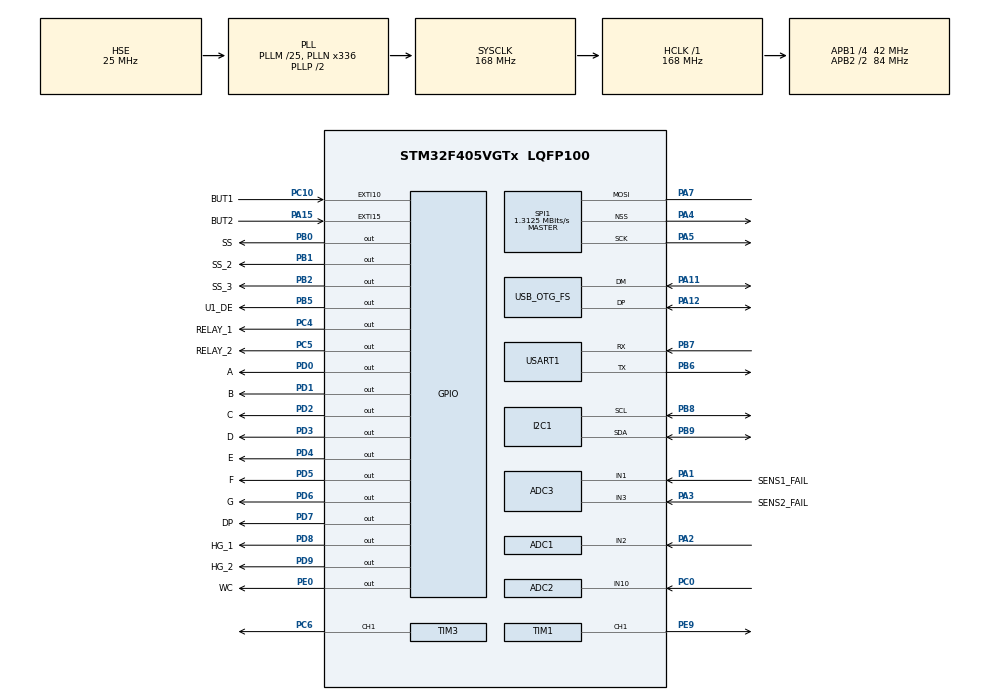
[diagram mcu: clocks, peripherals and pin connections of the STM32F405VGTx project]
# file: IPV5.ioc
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ADC1.Channel-4\#ChannelRegularConversion=ADC_CHANNEL_2
ADC1.ClockPrescaler=ADC_CLOCK_SYNC_PCLK_DIV8
ADC1.ContinuousConvMode=DISABLE
ADC1.DMAContinuousRequests=ENABLE
ADC1.DataAlign=ADC_DATAALIGN_RIGHT
ADC1.DiscontinuousConvMode=DISABLE
ADC1.EOCSelection=ADC_EOC_SINGLE_CONV
ADC1.EnableAnalogWatchDog=false
ADC1.ExternalTrigConv=ADC_EXTERNALTRIGCONV_T2_TRGO
ADC1.ExternalTrigConvEdge=ADC_EXTERNALTRIGCONVEDGE_RISING
ADC1.InjNumberOfConversion=0
ADC1.NbrOfConversion=1
ADC1.NbrOfConversionFlag=1
ADC1.Rank-4\#ChannelRegularConversion=1
ADC1.Resolution=ADC_RESOLUTION_12B
ADC1.SamplingTime-4\#ChannelRegularConversion=ADC_SAMPLETIME_15CYCLES
ADC1.ScanConvMode=DISABLE
ADC1.master=1
ADC2.Channel-0\#ChannelRegularConversion=ADC_CHANNEL_10
ADC2.ClockPrescaler=ADC_CLOCK_SYNC_PCLK_DIV8
ADC2.ExternalTrigConv=ADC_EXTERNALTRIGCONV_T2_TRGO
ADC2.ExternalTrigConvEdge=ADC_EXTERNALTRIGCONVEDGE_FALLING
ADC2.NbrOfConversionFlag=1
ADC2.Rank-0\#ChannelRegularConversion=1
ADC2.SamplingTime-0\#ChannelRegularConversion=ADC_SAMPLETIME_3CYCLES
ADC3.Channel-0\#ChannelRegularConversion=ADC_CHANNEL_1
ADC3.Channel-1\#ChannelInjectedConversion=ADC_CHANNEL_1
ADC3.Channel-2\#ChannelInjectedConversion=ADC_CHANNEL_3
ADC3.ClockPrescaler=ADC_CLOCK_SYNC_PCLK_DIV8
ADC3.ContinuousConvMode=DISABLE
ADC3.DiscontinuousConvMode=DISABLE
ADC3.ExternalTrigInjecConv=ADC_INJECTED_SOFTWARE_START
ADC3.InjNumberOfConversion=2
ADC3.InjectedConvMode=AutoInjected
ADC3.InjectedOffset-1\#ChannelInjectedConversion=0
ADC3.InjectedOffset-2\#ChannelInjectedConversion=0
ADC3.InjectedRank-1\#ChannelInjectedConversion=1
ADC3.InjectedRank-2\#ChannelInjectedConversion=2
ADC3.NbrOfConversion=1
ADC3.NbrOfConversionFlag=1
ADC3.Rank-0\#ChannelRegularConversion=1
ADC3.SamplingTime-0\#ChannelRegularConversion=ADC_SAMPLETIME_480CYCLES
ADC3.SamplingTime-1\#ChannelInjectedConversion=ADC_SAMPLETIME_480CYCLES
ADC3.SamplingTime-2\#ChannelInjectedConversion=ADC_SAMPLETIME_480CYCLES
ADC3.ScanConvMode=ENABLE
Dma.ADC1.6.Direction=DMA_PERIPH_TO_MEMORY
Dma.ADC1.6.FIFOMode=DMA_FIFOMODE_ENABLE
Dma.ADC1.6.FIFOThreshold=DMA_FIFO_THRESHOLD_FULL
Dma.ADC1.6.Instance=DMA2_Stream4
Dma.ADC1.6.MemBurst=DMA_MBURST_INC4
Dma.ADC1.6.MemDataAlignment=DMA_MDATAALIGN_WORD
Dma.ADC1.6.MemInc=DMA_MINC_ENABLE
Dma.ADC1.6.Mode=DMA_NORMAL
Dma.ADC1.6.PeriphBurst=DMA_PBURST_SINGLE
Dma.ADC1.6.PeriphDataAlignment=DMA_PDATAALIGN_WORD
Dma.ADC1.6.PeriphInc=DMA_PINC_DISABLE
Dma.ADC1.6.Priority=DMA_PRIORITY_MEDIUM
Dma.ADC2.7.Direction=DMA_PERIPH_TO_MEMORY
Dma.ADC2.7.FIFOMode=DMA_FIFOMODE_ENABLE
Dma.ADC2.7.FIFOThreshold=DMA_FIFO_THRESHOLD_FULL
Dma.ADC2.7.Instance=DMA2_Stream2
Dma.ADC2.7.MemBurst=DMA_MBURST_INC4
Dma.ADC2.7.MemDataAlignment=DMA_MDATAALIGN_WORD
Dma.ADC2.7.MemInc=DMA_MINC_ENABLE
Dma.ADC2.7.Mode=DMA_NORMAL
Dma.ADC2.7.PeriphBurst=DMA_PBURST_SINGLE
Dma.ADC2.7.PeriphDataAlignment=DMA_PDATAALIGN_WORD
Dma.ADC2.7.PeriphInc=DMA_PINC_DISABLE
Dma.ADC2.7.Priority=DMA_PRIORITY_MEDIUM
Dma.I2C1_RX.1.Direction=DMA_PERIPH_TO_MEMORY
Dma.I2C1_RX.1.FIFOMode=DMA_FIFOMODE_DISABLE
Dma.I2C1_RX.1.Instance=DMA1_Stream0
Dma.I2C1_RX.1.MemDataAlignment=DMA_MDATAALIGN_BYTE
Dma.I2C1_RX.1.MemInc=DMA_MINC_ENABLE
Dma.I2C1_RX.1.Mode=DMA_NORMAL
Dma.I2C1_RX.1.PeriphDataAlignment=DMA_PDATAALIGN_BYTE
Dma.I2C1_RX.1.PeriphInc=DMA_PINC_DISABLE
Dma.I2C1_RX.1.Priority=DMA_PRIORITY_LOW
Dma.I2C1_TX.0.Direction=DMA_MEMORY_TO_PERIPH
Dma.I2C1_TX.0.FIFOMode=DMA_FIFOMODE_DISABLE
Dma.I2C1_TX.0.Instance=DMA1_Stream7
Dma.I2C1_TX.0.MemDataAlignment=DMA_MDATAALIGN_BYTE
Dma.I2C1_TX.0.MemInc=DMA_MINC_ENABLE
Dma.I2C1_TX.0.Mode=DMA_NORMAL
Dma.I2C1_TX.0.PeriphDataAlignment=DMA_PDATAALIGN_BYTE
Dma.I2C1_TX.0.PeriphInc=DMA_PINC_DISABLE
Dma.I2C1_TX.0.Priority=DMA_PRIORITY_LOW
Dma.Request0=I2C1_TX
Dma.Request1=I2C1_RX
Dma.Request2=SPI1_RX
Dma.Request3=SPI1_TX
Dma.Request4=USART1_RX
Dma.Request5=USART1_TX
Dma.Request6=ADC1
Dma.Request7=ADC2
Dma.Request8=TIM8_UP
Dma.SPI1_RX.2.Direction=DMA_PERIPH_TO_MEMORY
Dma.SPI1_RX.2.FIFOMode=DMA_FIFOMODE_ENABLE
Dma.SPI1_RX.2.FIFOThreshold=DMA_FIFO_THRESHOLD_FULL
Dma.SPI1_RX.2.Instance=DMA2_Stream0
Dma.SPI1_RX.2.MemBurst=DMA_MBURST_SINGLE
Dma.SPI1_RX.2.MemDataAlignment=DMA_MDATAALIGN_HALFWORD
Dma.SPI1_RX.2.MemInc=DMA_MINC_ENABLE
Dma.SPI1_RX.2.Mode=DMA_NORMAL
Dma.SPI1_RX.2.PeriphBurst=DMA_PBURST_SINGLE
Dma.SPI1_RX.2.PeriphDataAlignment=DMA_PDATAALIGN_HALFWORD
Dma.SPI1_RX.2.PeriphInc=DMA_PINC_DISABLE
Dma.SPI1_RX.2.Priority=DMA_PRIORITY_MEDIUM
Dma.SPI1_TX.3.Direction=DMA_MEMORY_TO_PERIPH
Dma.SPI1_TX.3.FIFOMode=DMA_FIFOMODE_ENABLE
Dma.SPI1_TX.3.FIFOThreshold=DMA_FIFO_THRESHOLD_FULL
Dma.SPI1_TX.3.Instance=DMA2_Stream3
Dma.SPI1_TX.3.MemBurst=DMA_MBURST_SINGLE
Dma.SPI1_TX.3.MemDataAlignment=DMA_MDATAALIGN_HALFWORD
Dma.SPI1_TX.3.MemInc=DMA_MINC_ENABLE
Dma.SPI1_TX.3.Mode=DMA_NORMAL
Dma.SPI1_TX.3.PeriphBurst=DMA_PBURST_SINGLE
Dma.SPI1_TX.3.PeriphDataAlignment=DMA_PDATAALIGN_HALFWORD
Dma.SPI1_TX.3.PeriphInc=DMA_PINC_DISABLE
Dma.SPI1_TX.3.Priority=DMA_PRIORITY_LOW
Dma.TIM8_UP.8.Direction=DMA_MEMORY_TO_PERIPH
Dma.TIM8_UP.8.FIFOMode=DMA_FIFOMODE_ENABLE
Dma.TIM8_UP.8.FIFOThreshold=DMA_FIFO_THRESHOLD_FULL
Dma.TIM8_UP.8.Instance=DMA2_Stream1
Dma.TIM8_UP.8.MemBurst=DMA_MBURST_INC4
Dma.TIM8_UP.8.MemDataAlignment=DMA_MDATAALIGN_WORD
Dma.TIM8_UP.8.MemInc=DMA_MINC_ENABLE
Dma.TIM8_UP.8.Mode=DMA_CIRCULAR
Dma.TIM8_UP.8.PeriphBurst=DMA_PBURST_SINGLE
Dma.TIM8_UP.8.PeriphDataAlignment=DMA_PDATAALIGN_WORD
Dma.TIM8_UP.8.PeriphInc=DMA_PINC_DISABLE
Dma.TIM8_UP.8.Priority=DMA_PRIORITY_HIGH
Dma.USART1_RX.4.Direction=DMA_PERIPH_TO_MEMORY
Dma.USART1_RX.4.FIFOMode=DMA_FIFOMODE_ENABLE
Dma.USART1_RX.4.FIFOThreshold=DMA_FIFO_THRESHOLD_FULL
Dma.USART1_RX.4.Instance=DMA2_Stream5
Dma.USART1_RX.4.MemBurst=DMA_MBURST_SINGLE
Dma.USART1_RX.4.MemDataAlignment=DMA_MDATAALIGN_BYTE
Dma.USART1_RX.4.MemInc=DMA_MINC_ENABLE
Dma.USART1_RX.4.Mode=DMA_NORMAL
Dma.USART1_RX.4.PeriphBurst=DMA_PBURST_SINGLE
Dma.USART1_RX.4.PeriphDataAlignment=DMA_PDATAALIGN_BYTE
Dma.USART1_RX.4.PeriphInc=DMA_PINC_DISABLE
Dma.USART1_RX.4.Priority=DMA_PRIORITY_VERY_HIGH
Dma.USART1_TX.5.Direction=DMA_MEMORY_TO_PERIPH
Dma.USART1_TX.5.FIFOMode=DMA_FIFOMODE_DISABLE
Dma.USART1_TX.5.Instance=DMA2_Stream7
Dma.USART1_TX.5.MemDataAlignment=DMA_MDATAALIGN_BYTE
Dma.USART1_TX.5.MemInc=DMA_MINC_ENABLE
Dma.USART1_TX.5.Mode=DMA_NORMAL
Dma.USART1_TX.5.PeriphDataAlignment=DMA_PDATAALIGN_BYTE
Dma.USART1_TX.5.PeriphInc=DMA_PINC_DISABLE
Dma.USART1_TX.5.Priority=DMA_PRIORITY_LOW
FREERTOS.CountingSemaphores01=myCountingSem_S01,5,Static,myCountingSem_S01ControlBlock;myCountingSem_S02,5,Static,myCountingSem_S05;myCountingSemBUT1,2,Static,myCountingSemBUT1ControlBlock;myCountingSemBUT2,2,Static,myCountingSemBUT2ControlBlock;myCountingSemTIM4,2,Static,myCountingSemTIM4ControlBlock
FREERTOS.HEAP_NUMBER=1
FREERTOS.INCLUDE_vTaskDelete=0
FREERTOS.MEMORY_ALLOCATION=1
FREERTOS.Mutexes01=myMutex_SPI1,Static,myMutexSPI1ControlBlock;myMutexI2C1,Static,myMutexI2C1ControlBlock
FREERTOS.Tasks01=defaultTask,0,128,StartDefaultTask,Default,NULL,Static,defaultTaskBuffer,defaultTaskControlBlock;myTask_S1,1,500,StartTask_S1,Default,NULL,Static,myTask_S1Buffer,myTask_S1ControlBlock;myTask_S2,0,500,StartTask_S2,Default,NULL,Static,myTask_S2Buffer,myTask_S2ControlBlock;myTaskModbus,-1,128,StartTaskModbus,Default,NULL,Static,myTaskModbusBuffer,myTaskModbusControlBlock
FREERTOS.Timers01=myTimerBUT2,myTimerCallbackBUT2,osTimerPeriodic,Default,NULL,Static,myTimerBUT2ControlBlock;myTimerBUT1,myTimerCalbakBUT1,osTimerPeriodic,Default,NULL,Static,myTimerBUT1ControlBlock
FREERTOS.configCHECK_FOR_STACK_OVERFLOW=2
FREERTOS.configMAX_PRIORITIES=5
FREERTOS.configMINIMAL_STACK_SIZE=64
FREERTOS.configUSE_COUNTING_SEMAPHORES=1
FREERTOS.configUSE_MALLOC_FAILED_HOOK=0
FREERTOS.configUSE_TIMERS=1
I2C1.DutyCycle=I2C_DUTYCYCLE_2
I2C1.I2C_Mode=I2C_Fast
IWDG.Prescaler=IWDG_PRESCALER_128
Mcu.Family=STM32F4
Mcu.Name=STM32F405VGTx
Mcu.Package=LQFP100
NVIC.DMA1_Stream0_IRQn=true\:5\:0\:false\:false\:true\:true\:false
NVIC.DMA1_Stream7_IRQn=true\:5\:0\:false\:false\:true\:true\:false
NVIC.DMA2_Stream0_IRQn=true\:5\:0\:false\:false\:true\:true\:false
NVIC.DMA2_Stream1_IRQn=true\:5\:0\:false\:false\:true\:true\:false
NVIC.DMA2_Stream2_IRQn=true\:5\:0\:false\:false\:true\:true\:false
NVIC.DMA2_Stream3_IRQn=true\:5\:0\:false\:false\:true\:true\:false
NVIC.DMA2_Stream4_IRQn=true\:5\:0\:false\:false\:true\:true\:false
NVIC.DMA2_Stream5_IRQn=true\:5\:0\:false\:false\:true\:false\:false
NVIC.DMA2_Stream7_IRQn=true\:5\:0\:false\:false\:true\:true\:false
NVIC.EXTI15_10_IRQn=true\:5\:0\:false\:false\:true\:true\:true
NVIC.PriorityGroup=NVIC_PRIORITYGROUP_4
NVIC.USART1_IRQn=true\:5\:0\:false\:false\:true\:true\:true
PA0-WKUP.Mode=SYS_WakeUp0
PA0-WKUP.Signal=SYS_WKUP
PA1.GPIO_Label=SENS1_FAIL
PA1.Signal=ADCx_IN1
PA11.Mode=Device_Only
PA11.Signal=USB_OTG_FS_DM
PA12.Mode=Device_Only
PA12.Signal=USB_OTG_FS_DP
PA13.Mode=Trace_Asynchronous_SW
PA13.Signal=SYS_JTMS-SWDIO
PA14.Mode=Trace_Asynchronous_SW
PA14.Signal=SYS_JTCK-SWCLK
PA15.GPIO_Label=BUT2
PA15.GPIO_ModeDefaultEXTI=GPIO_MODE_IT_RISING_FALLING
PA15.Signal=GPXTI15
PA2.Signal=ADCx_IN2
PA3.GPIO_Label=SENS2_FAIL
PA3.Signal=ADCx_IN3
PA4.Mode=NSS_Signal_Hard_Output
PA4.Signal=SPI1_NSS
PA5.Mode=Simplex_Bidirectional_Master
PA5.Signal=SPI1_SCK
PA7.Mode=Simplex_Bidirectional_Master
PA7.Signal=SPI1_MOSI
PB0.GPIO_Label=SS
PB0.GPIO_Speed=GPIO_SPEED_FREQ_VERY_HIGH
PB0.Signal=GPIO_Output
PB1.GPIO_Label=SS_2
PB1.GPIO_Speed=GPIO_SPEED_FREQ_VERY_HIGH
PB1.Signal=GPIO_Output
PB2.GPIO_Label=SS_3
PB2.GPIO_Speed=GPIO_SPEED_FREQ_VERY_HIGH
PB2.Signal=GPIO_Output
PB3.Mode=Trace_Asynchronous_SW
PB3.Signal=SYS_JTDO-SWO
PB5.GPIO_Label=U1_DE
PB5.Signal=GPIO_Output
PB6.Mode=Asynchronous
PB6.Signal=USART1_TX
PB7.Mode=Asynchronous
PB7.Signal=USART1_RX
PB8.Mode=I2C
PB8.Signal=I2C1_SCL
PB9.Mode=I2C
PB9.Signal=I2C1_SDA
PC0.Signal=ADCx_IN10
PC10.GPIO_Label=BUT1
PC10.GPIO_ModeDefaultEXTI=GPIO_MODE_IT_RISING_FALLING
PC10.Signal=GPXTI10
PC4.GPIO_Label=RELAY_1
PC4.Signal=GPIO_Output
PC5.GPIO_Label=RELAY_2
PC5.Signal=GPIO_Output
PC6.Signal=S_TIM3_CH1
PD0.GPIO_Label=A
PD0.Signal=GPIO_Output
PD1.GPIO_Label=B
PD1.Signal=GPIO_Output
PD2.GPIO_Label=C
PD2.Signal=GPIO_Output
PD3.GPIO_Label=D
PD3.Signal=GPIO_Output
PD4.GPIO_Label=E
PD4.Signal=GPIO_Output
PD5.GPIO_Label=F
PD5.Signal=GPIO_Output
PD6.GPIO_Label=G
PD6.Signal=GPIO_Output
PD7.GPIO_Label=DP
PD7.Signal=GPIO_Output
PD8.GPIO_Label=HG_1
PD8.Signal=GPIO_Output
PD9.GPIO_Label=HG_2
PD9.Signal=GPIO_Output
PE0.GPIO_Label=WC
PE0.Signal=GPIO_Output
PE9.Signal=S_TIM1_CH1
PH0-OSC_IN.Mode=HSE-External-Oscillator
PH0-OSC_IN.Signal=RCC_OSC_IN
PH1-OSC_OUT.Mode=HSE-External-Oscillator
PH1-OSC_OUT.Signal=RCC_OSC_OUT
ProjectManager.HeapSize=0x200
ProjectManager.StackSize=0x400
ProjectManager.TargetToolchain=TrueSTUDIO
RCC.48MHZClocksFreq_Value=48000000
RCC.AHBFreq_Value=168000000
RCC.APB1CLKDivider=RCC_HCLK_DIV4
RCC.APB1Freq_Value=42000000
RCC.APB1TimFreq_Value=84000000
RCC.APB2CLKDivider=RCC_HCLK_DIV2
RCC.APB2Freq_Value=84000000
RCC.APB2TimFreq_Value=168000000
RCC.CortexFreq_Value=168000000
RCC.HCLKFreq_Value=168000000
RCC.HSE_VALUE=25000000
RCC.HSI_VALUE=16000000
RCC.LSE_VALUE=32768
RCC.PLLM=25
RCC.PLLN=336
RCC.PLLQ=7
RCC.RCC_RTC_Clock_Source_FROM_HSE=RCC_RTCCLKSOURCE_HSE_DIV31
RCC.SYSCLKFreq_VALUE=168000000
RCC.SYSCLKSource=RCC_SYSCLKSOURCE_PLLCLK
RCC.VCOOutputFreq_Value=336000000
SH.ADCx_IN1.0=ADC3_IN1,IN1
SH.ADCx_IN10.0=ADC2_IN10,IN10
SH.ADCx_IN2.0=ADC1_IN2,IN2
SH.ADCx_IN3.0=ADC3_IN3,IN3
SH.S_TIM1_CH1.0=TIM1_CH1,Output Compare1 CH1
SH.S_TIM3_CH1.0=TIM3_CH1,PWM Generation1 CH1
SPI1.BaudRatePrescaler=SPI_BAUDRATEPRESCALER_64
SPI1.CalculateBaudRate=1.3125 MBits/s
SPI1.DataSize=SPI_DATASIZE_16BIT
SPI1.Direction=SPI_DIRECTION_1LINE
SPI1.Mode=SPI_MODE_MASTER
SPI1.VirtualNSS=VM_NSSHARD
SPI1.VirtualType=VM_MASTER
TIM1.Channel-Output\ Compare1\ CH1=TIM_CHANNEL_1
TIM1.Period=1050
TIM1.Prescaler=0
TIM1.TIM_MasterOutputTrigger=TIM_TRGO_UPDATE
TIM2.Period=500
TIM2.Prescaler=21
TIM2.TIM_MasterOutputTrigger=TIM_TRGO_UPDATE
TIM3.Channel-PWM\ Generation1\ CH1=TIM_CHANNEL_1
TIM3.OCFastMode_PWM-PWM\ Generation1\ CH1=TIM_OCFAST_ENABLE
TIM3.Period=65535
TIM3.TIM_MasterOutputTrigger=TIM_TRGO_UPDATE
TIM8.ClockDivision=TIM_CLOCKDIVISION_DIV4
TIM8.Period=25
TIM8.Prescaler=42000
USART1.VirtualMode=VM_ASYNC
USB_OTG_FS.VirtualMode=Device_Only
VP_CRC_VS_CRC.Mode=CRC_Activate
VP_FREERTOS_VS_ENABLE.Mode=Enabled
VP_IWDG_VS_IWDG.Mode=IWDG_Activate
VP_RNG_VS_RNG.Mode=RNG_Activate
VP_RTC_VS_RTC_Activate.Mode=RTC_Enabled
VP_RTC_VS_RTC_Calendar.Mode=RTC_Calendar
VP_TIM1_VS_ClockSourceINT.Mode=Internal
VP_TIM2_VS_ClockSourceINT.Mode=Internal
VP_TIM3_VS_ClockSourceINT.Mode=Internal
VP_TIM8_VS_ClockSourceINT.Mode=Internal
VP_WWDG_VS_WWDG.Mode=WWDG_Activate
board=IPV5

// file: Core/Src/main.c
/* USER CODE BEGIN Header */
/**
  ******************************************************************************
  * @file           : main.c
  * @brief          : Main program body
  ******************************************************************************
  * This notice applies to any and all portions of this file
  * that are not between comment pairs USER CODE BEGIN and
  * USER CODE END. Other portions of this file, whether
  * inserted by the user or by software development tools
  * are owned by their respective copyright owners.
  *
  * Copyright (c) 2020 STMicroelectronics International N.V.
  * All rights reserved.
  *
  * Redistribution and use in source and binary forms, with or without
  * modification, are permitted, provided that the following conditions are met:
  *
  * 1. Redistribution of source code must retain the above copyright notice,
  *    this list of conditions and the following disclaimer.
  * 2. Redistributions in binary form must reproduce the above copyright notice,
  *    this list of conditions and the following disclaimer in the documentation
  *    and/or other materials provided with the distribution.
  * 3. Neither the name of STMicroelectronics nor the names of other
  *    contributors to this software may be used to endorse or promote products
  *    derived from this software without specific written permission.
  * 4. This software, including modifications and/or derivative works of this
  *    software, must execute solely and exclusively on microcontroller or
  *    microprocessor devices manufactured by or for STMicroelectronics.
  * 5. Redistribution and use of this software other than as permitted under
  *    this license is void and will automatically terminate your rights under
  *    this license.
  *
  * THIS SOFTWARE IS PROVIDED BY STMICROELECTRONICS AND CONTRIBUTORS "AS IS"
  * AND ANY EXPRESS, IMPLIED OR STATUTORY WARRANTIES, INCLUDING, BUT NOT
  * LIMITED TO, THE IMPLIED WARRANTIES OF MERCHANTABILITY, FITNESS FOR A
  * PARTICULAR PURPOSE AND NON-INFRINGEMENT OF THIRD PARTY INTELLECTUAL PROPERTY
  * RIGHTS ARE DISCLAIMED TO THE FULLEST EXTENT PERMITTED BY LAW. IN NO EVENT
  * SHALL STMICROELECTRONICS OR CONTRIBUTORS BE LIABLE FOR ANY DIRECT, INDIRECT,
  * INCIDENTAL, SPECIAL, EXEMPLARY, OR CONSEQUENTIAL DAMAGES (INCLUDING, BUT NOT
  * LIMITED TO, PROCUREMENT OF SUBSTITUTE GOODS OR SERVICES; LOSS OF USE, DATA,
  * OR PROFITS; OR BUSINESS INTERRUPTION) HOWEVER CAUSED AND ON ANY THEORY OF
  * LIABILITY, WHETHER IN CONTRACT, STRICT LIABILITY, OR TORT (INCLUDING
  * NEGLIGENCE OR OTHERWISE) ARISING IN ANY WAY OUT OF THE USE OF THIS SOFTWARE,
  * EVEN IF ADVISED OF THE POSSIBILITY OF SUCH DAMAGE.
  *
  ******************************************************************************
  */
/* USER CODE END Header */

#include "main.h"
#include "cmsis_os.h"

ADC_HandleTypeDef hadc1;
ADC_HandleTypeDef hadc2;
ADC_HandleTypeDef hadc3;
DMA_HandleTypeDef hdma_adc1;
DMA_HandleTypeDef hdma_adc2;

CRC_HandleTypeDef hcrc;

I2C_HandleTypeDef hi2c1;
DMA_HandleTypeDef hdma_i2c1_tx;
DMA_HandleTypeDef hdma_i2c1_rx;

IWDG_HandleTypeDef hiwdg;

RNG_HandleTypeDef hrng;

RTC_HandleTypeDef hrtc;

SPI_HandleTypeDef hspi1;
DMA_HandleTypeDef hdma_spi1_rx;
DMA_HandleTypeDef hdma_spi1_tx;

TIM_HandleTypeDef htim1;
TIM_HandleTypeDef htim2;
TIM_HandleTypeDef htim3;
TIM_HandleTypeDef htim8;
DMA_HandleTypeDef hdma_tim8_up;

UART_HandleTypeDef huart1;
DMA_HandleTypeDef hdma_usart1_rx;
DMA_HandleTypeDef hdma_usart1_tx;

PCD_HandleTypeDef hpcd_USB_OTG_FS;

WWDG_HandleTypeDef hwwdg;

osThreadId defaultTaskHandle;
uint32_t defaultTaskBuffer[ 128 ];
osStaticThreadDef_t defaultTaskControlBlock;
osThreadId myTask_S1Handle;
uint32_t myTask_S1Buffer[ 500 ];
osStaticThreadDef_t myTask_S1ControlBlock;
osThreadId myTask_S2Handle;
uint32_t myTask_S2Buffer[ 500 ];
osStaticThreadDef_t myTask_S2ControlBlock;
osThreadId myTaskModbusHandle;
uint32_t myTaskModbusBuffer[ 128 ];
osStaticThreadDef_t myTaskModbusControlBlock;
osTimerId myTimerBUT2Handle;
osStaticTimerDef_t myTimerBUT2ControlBlock;
osTimerId myTimerBUT1Handle;
osStaticTimerDef_t myTimerBUT1ControlBlock;
osMutexId myMutex_SPI1Handle;
osStaticMutexDef_t myMutexSPI1ControlBlock;
osMutexId myMutexI2C1Handle;
osStaticMutexDef_t myMutexI2C1ControlBlock;
osSemaphoreId myCountingSem_S01Handle;
osStaticSemaphoreDef_t myCountingSem_S01ControlBlock;
osSemaphoreId myCountingSem_S02Handle;
osStaticSemaphoreDef_t myCountingSem_S05;
osSemaphoreId myCountingSemBUT1Handle;
osStaticSemaphoreDef_t myCountingSemBUT1ControlBlock;
osSemaphoreId myCountingSemBUT2Handle;
osStaticSemaphoreDef_t myCountingSemBUT2ControlBlock;
osSemaphoreId myCountingSemTIM4Handle;
osStaticSemaphoreDef_t myCountingSemTIM4ControlBlock;

void SystemClock_Config(void);
static void MX_GPIO_Init(void);
static void MX_DMA_Init(void);
static void MX_ADC1_Init(void);
static void MX_CRC_Init(void);
static void MX_I2C1_Init(void);
static void MX_RNG_Init(void);
static void MX_RTC_Init(void);
static void MX_SPI1_Init(void);
static void MX_TIM1_Init(void);
static void MX_TIM3_Init(void);
static void MX_USART1_UART_Init(void);
static void MX_TIM2_Init(void);
static void MX_USB_OTG_FS_PCD_Init(void);
static void MX_IWDG_Init(void);
static void MX_WWDG_Init(void);
static void MX_ADC2_Init(void);
static void MX_TIM8_Init(void);
static void MX_ADC3_Init(void);
void StartDefaultTask(void const * argument);
void StartTask_S1(void const * argument);
void StartTask_S2(void const * argument);
void StartTaskModbus(void const * argument);
void myTimerCallbackBUT2(void const * argument);
void myTimerCalbakBUT1(void const * argument);

int main(void)
{

  /* MCU Configuration--------------------------------------------------------*/

  /* Reset of all peripherals, Initializes the Flash interface and the Systick. */
  HAL_Init();

  /* Configure the system clock */
  SystemClock_Config();

  /* Initialize all configured peripherals */
  MX_GPIO_Init();
  MX_DMA_Init();
  MX_ADC1_Init();
  MX_CRC_Init();
  MX_I2C1_Init();
  MX_RNG_Init();
  MX_RTC_Init();
  MX_SPI1_Init();
  MX_TIM1_Init();
  MX_TIM3_Init();
  MX_USART1_UART_Init();
  MX_TIM2_Init();
  MX_USB_OTG_FS_PCD_Init();
  MX_IWDG_Init();
  MX_WWDG_Init();
  MX_ADC2_Init();
  MX_TIM8_Init();
  MX_ADC3_Init();

  /* Create the mutex(es) */
  /* definition and creation of myMutex_SPI1 */
  osMutexStaticDef(myMutex_SPI1, &myMutexSPI1ControlBlock);
  myMutex_SPI1Handle = osMutexCreate(osMutex(myMutex_SPI1));

  /* definition and creation of myMutexI2C1 */
  osMutexStaticDef(myMutexI2C1, &myMutexI2C1ControlBlock);
  myMutexI2C1Handle = osMutexCreate(osMutex(myMutexI2C1));

  /* Create the semaphores(s) */
  /* definition and creation of myCountingSem_S01 */
  osSemaphoreStaticDef(myCountingSem_S01, &myCountingSem_S01ControlBlock);
  myCountingSem_S01Handle = osSemaphoreCreate(osSemaphore(myCountingSem_S01), 5);

  /* definition and creation of myCountingSem_S02 */
  osSemaphoreStaticDef(myCountingSem_S02, &myCountingSem_S05);
  myCountingSem_S02Handle = osSemaphoreCreate(osSemaphore(myCountingSem_S02), 5);

  /* definition and creation of myCountingSemBUT1 */
  osSemaphoreStaticDef(myCountingSemBUT1, &myCountingSemBUT1ControlBlock);
  myCountingSemBUT1Handle = osSemaphoreCreate(osSemaphore(myCountingSemBUT1), 2);

  /* definition and creation of myCountingSemBUT2 */
  osSemaphoreStaticDef(myCountingSemBUT2, &myCountingSemBUT2ControlBlock);
  myCountingSemBUT2Handle = osSemaphoreCreate(osSemaphore(myCountingSemBUT2), 2);

  /* definition and creation of myCountingSemTIM4 */
  osSemaphoreStaticDef(myCountingSemTIM4, &myCountingSemTIM4ControlBlock);
  myCountingSemTIM4Handle = osSemaphoreCreate(osSemaphore(myCountingSemTIM4), 2);

  /* Create the timer(s) */
  /* definition and creation of myTimerBUT2 */
  osTimerStaticDef(myTimerBUT2, myTimerCallbackBUT2, &myTimerBUT2ControlBlock);
  myTimerBUT2Handle = osTimerCreate(osTimer(myTimerBUT2), osTimerPeriodic, NULL);

  /* definition and creation of myTimerBUT1 */
  osTimerStaticDef(myTimerBUT1, myTimerCalbakBUT1, &myTimerBUT1ControlBlock);
  myTimerBUT1Handle = osTimerCreate(osTimer(myTimerBUT1), osTimerPeriodic, NULL);

  /* Create the thread(s) */
  /* definition and creation of defaultTask */
  osThreadStaticDef(defaultTask, StartDefaultTask, osPriorityNormal, 0, 128, defaultTaskBuffer, &defaultTaskControlBlock);
  defaultTaskHandle = osThreadCreate(osThread(defaultTask), NULL);

  /* definition and creation of myTask_S1 */
  osThreadStaticDef(myTask_S1, StartTask_S1, osPriorityAboveNormal, 0, 500, myTask_S1Buffer, &myTask_S1ControlBlock);
  myTask_S1Handle = osThreadCreate(osThread(myTask_S1), NULL);

  /* definition and creation of myTask_S2 */
  osThreadStaticDef(myTask_S2, StartTask_S2, osPriorityNormal, 0, 500, myTask_S2Buffer, &myTask_S2ControlBlock);
  myTask_S2Handle = osThreadCreate(osThread(myTask_S2), NULL);

  /* definition and creation of myTaskModbus */
  osThreadStaticDef(myTaskModbus, StartTaskModbus, osPriorityBelowNormal, 0, 128, myTaskModbusBuffer, &myTaskModbusControlBlock);
  myTaskModbusHandle = osThreadCreate(osThread(myTaskModbus), NULL);

  /* Start scheduler */
  osKernelStart();

  /* We should never get here as control is now taken by the scheduler */

  /* Infinite loop */
  while (1)
  {

  }
}

void SystemClock_Config(void)
{
  RCC_OscInitTypeDef RCC_OscInitStruct = {0};
  RCC_ClkInitTypeDef RCC_ClkInitStruct = {0};
  RCC_PeriphCLKInitTypeDef PeriphClkInitStruct = {0};

  /**Configure the main internal regulator output voltage
  */
  __HAL_RCC_PWR_CLK_ENABLE();
  __HAL_PWR_VOLTAGESCALING_CONFIG(PWR_REGULATOR_VOLTAGE_SCALE1);
  /**Initializes the CPU, AHB and APB busses clocks
  */
  RCC_OscInitStruct.OscillatorType = RCC_OSCILLATORTYPE_LSI|RCC_OSCILLATORTYPE_HSE;
  RCC_OscInitStruct.HSEState = RCC_HSE_ON;
  RCC_OscInitStruct.LSIState = RCC_LSI_ON;
  RCC_OscInitStruct.PLL.PLLState = RCC_PLL_ON;
  RCC_OscInitStruct.PLL.PLLSource = RCC_PLLSOURCE_HSE;
  RCC_OscInitStruct.PLL.PLLM = 25;
  RCC_OscInitStruct.PLL.PLLN = 336;
  RCC_OscInitStruct.PLL.PLLP = RCC_PLLP_DIV2;
  RCC_OscInitStruct.PLL.PLLQ = 7;
  if (HAL_RCC_OscConfig(&RCC_OscInitStruct) != HAL_OK)
  {
    Error_Handler();
  }
  /**Initializes the CPU, AHB and APB busses clocks
  */
  RCC_ClkInitStruct.ClockType = RCC_CLOCKTYPE_HCLK|RCC_CLOCKTYPE_SYSCLK
                              |RCC_CLOCKTYPE_PCLK1|RCC_CLOCKTYPE_PCLK2;
  RCC_ClkInitStruct.SYSCLKSource = RCC_SYSCLKSOURCE_PLLCLK;
  RCC_ClkInitStruct.AHBCLKDivider = RCC_SYSCLK_DIV1;
  RCC_ClkInitStruct.APB1CLKDivider = RCC_HCLK_DIV4;
  RCC_ClkInitStruct.APB2CLKDivider = RCC_HCLK_DIV2;

  if (HAL_RCC_ClockConfig(&RCC_ClkInitStruct, FLASH_LATENCY_5) != HAL_OK)
  {
    Error_Handler();
  }
  PeriphClkInitStruct.PeriphClockSelection = RCC_PERIPHCLK_RTC;
  PeriphClkInitStruct.RTCClockSelection = RCC_RTCCLKSOURCE_LSI;
  if (HAL_RCCEx_PeriphCLKConfig(&PeriphClkInitStruct) != HAL_OK)
  {
    Error_Handler();
  }
}

static void MX_ADC1_Init(void)
{

  ADC_ChannelConfTypeDef sConfig = {0};

  /**Configure the global features of the ADC (Clock, Resolution, Data Alignment and number of conversion)
  */
  hadc1.Instance = ADC1;
  hadc1.Init.ClockPrescaler = ADC_CLOCK_SYNC_PCLK_DIV8;
  hadc1.Init.Resolution = ADC_RESOLUTION_12B;
  hadc1.Init.ScanConvMode = DISABLE;
  hadc1.Init.ContinuousConvMode = DISABLE;
  hadc1.Init.DiscontinuousConvMode = DISABLE;
  hadc1.Init.ExternalTrigConvEdge = ADC_EXTERNALTRIGCONVEDGE_RISING;
  hadc1.Init.ExternalTrigConv = ADC_EXTERNALTRIGCONV_T2_TRGO;
  hadc1.Init.DataAlign = ADC_DATAALIGN_RIGHT;
  hadc1.Init.NbrOfConversion = 1;
  hadc1.Init.DMAContinuousRequests = ENABLE;
  hadc1.Init.EOCSelection = ADC_EOC_SINGLE_CONV;
  if (HAL_ADC_Init(&hadc1) != HAL_OK)
  {
    Error_Handler();
  }
  /**Configure for the selected ADC regular channel its corresponding rank in the sequencer and its sample time.
  */
  sConfig.Channel = ADC_CHANNEL_2;
  sConfig.Rank = 1;
  sConfig.SamplingTime = ADC_SAMPLETIME_15CYCLES;
  if (HAL_ADC_ConfigChannel(&hadc1, &sConfig) != HAL_OK)
  {
    Error_Handler();
  }

}

static void MX_ADC2_Init(void)
{

  ADC_ChannelConfTypeDef sConfig = {0};

  /**Configure the global features of the ADC (Clock, Resolution, Data Alignment and number of conversion)
  */
  hadc2.Instance = ADC2;
  hadc2.Init.ClockPrescaler = ADC_CLOCK_SYNC_PCLK_DIV8;
  hadc2.Init.Resolution = ADC_RESOLUTION_12B;
  hadc2.Init.ScanConvMode = DISABLE;
  hadc2.Init.ContinuousConvMode = DISABLE;
  hadc2.Init.DiscontinuousConvMode = DISABLE;
  hadc2.Init.ExternalTrigConvEdge = ADC_EXTERNALTRIGCONVEDGE_FALLING;
  hadc2.Init.ExternalTrigConv = ADC_EXTERNALTRIGCONV_T2_TRGO;
  hadc2.Init.DataAlign = ADC_DATAALIGN_RIGHT;
  hadc2.Init.NbrOfConversion = 1;
  hadc2.Init.DMAContinuousRequests = DISABLE;
  hadc2.Init.EOCSelection = ADC_EOC_SINGLE_CONV;
  if (HAL_ADC_Init(&hadc2) != HAL_OK)
  {
    Error_Handler();
  }
  /**Configure for the selected ADC regular channel its corresponding rank in the sequencer and its sample time.
  */
  sConfig.Channel = ADC_CHANNEL_10;
  sConfig.Rank = 1;
  sConfig.SamplingTime = ADC_SAMPLETIME_3CYCLES;
  if (HAL_ADC_ConfigChannel(&hadc2, &sConfig) != HAL_OK)
  {
    Error_Handler();
  }

}

static void MX_ADC3_Init(void)
{

  ADC_ChannelConfTypeDef sConfig = {0};
  ADC_InjectionConfTypeDef sConfigInjected = {0};

  /**Configure the global features of the ADC (Clock, Resolution, Data Alignment and number of conversion)
  */
  hadc3.Instance = ADC3;
  hadc3.Init.ClockPrescaler = ADC_CLOCK_SYNC_PCLK_DIV8;
  hadc3.Init.Resolution = ADC_RESOLUTION_12B;
  hadc3.Init.ScanConvMode = ENABLE;
  hadc3.Init.ContinuousConvMode = DISABLE;
  hadc3.Init.DiscontinuousConvMode = DISABLE;
  hadc3.Init.ExternalTrigConvEdge = ADC_EXTERNALTRIGCONVEDGE_NONE;
  hadc3.Init.ExternalTrigConv = ADC_SOFTWARE_START;
  hadc3.Init.DataAlign = ADC_DATAALIGN_RIGHT;
  hadc3.Init.NbrOfConversion = 1;
  hadc3.Init.DMAContinuousRequests = DISABLE;
  hadc3.Init.EOCSelection = ADC_EOC_SINGLE_CONV;
  if (HAL_ADC_Init(&hadc3) != HAL_OK)
  {
    Error_Handler();
  }
  /**Configure for the selected ADC regular channel its corresponding rank in the sequencer and its sample time.
  */
  sConfig.Channel = ADC_CHANNEL_1;
  sConfig.Rank = 1;
  sConfig.SamplingTime = ADC_SAMPLETIME_480CYCLES;
  if (HAL_ADC_ConfigChannel(&hadc3, &sConfig) != HAL_OK)
  {
    Error_Handler();
  }
  /**Configures for the selected ADC injected channel its corresponding rank in the sequencer and its sample time
  */
  sConfigInjected.InjectedChannel = ADC_CHANNEL_1;
  sConfigInjected.InjectedRank = 1;
  sConfigInjected.InjectedNbrOfConversion = 2;
  sConfigInjected.InjectedSamplingTime = ADC_SAMPLETIME_480CYCLES;
  sConfigInjected.ExternalTrigInjecConvEdge = ADC_EXTERNALTRIGINJECCONVEDGE_NONE;
  sConfigInjected.ExternalTrigInjecConv = ADC_INJECTED_SOFTWARE_START;
  sConfigInjected.AutoInjectedConv = ENABLE;
  sConfigInjected.InjectedDiscontinuousConvMode = DISABLE;
  sConfigInjected.InjectedOffset = 0;
  if (HAL_ADCEx_InjectedConfigChannel(&hadc3, &sConfigInjected) != HAL_OK)
  {
    Error_Handler();
  }
  /**Configures for the selected ADC injected channel its corresponding rank in the sequencer and its sample time
  */
  sConfigInjected.InjectedChannel = ADC_CHANNEL_3;
  if (HAL_ADCEx_InjectedConfigChannel(&hadc3, &sConfigInjected) != HAL_OK)
  {
    Error_Handler();
  }

}

static void MX_CRC_Init(void)
{

  hcrc.Instance = CRC;
  if (HAL_CRC_Init(&hcrc) != HAL_OK)
  {
    Error_Handler();
  }

}

static void MX_I2C1_Init(void)
{

  hi2c1.Instance = I2C1;
  hi2c1.Init.ClockSpeed = 400000;
  hi2c1.Init.DutyCycle = I2C_DUTYCYCLE_2;
  hi2c1.Init.OwnAddress1 = 0;
  hi2c1.Init.AddressingMode = I2C_ADDRESSINGMODE_7BIT;
  hi2c1.Init.DualAddressMode = I2C_DUALADDRESS_DISABLE;
  hi2c1.Init.OwnAddress2 = 0;
  hi2c1.Init.GeneralCallMode = I2C_GENERALCALL_DISABLE;
  hi2c1.Init.NoStretchMode = I2C_NOSTRETCH_DISABLE;
  if (HAL_I2C_Init(&hi2c1) != HAL_OK)
  {
    Error_Handler();
  }

}

static void MX_IWDG_Init(void)
{

  hiwdg.Instance = IWDG;
  hiwdg.Init.Prescaler = IWDG_PRESCALER_128;
  hiwdg.Init.Reload = 4095;
  if (HAL_IWDG_Init(&hiwdg) != HAL_OK)
  {
    Error_Handler();
  }

}

static void MX_RNG_Init(void)
{

  hrng.Instance = RNG;
  if (HAL_RNG_Init(&hrng) != HAL_OK)
  {
    Error_Handler();
  }

}

static void MX_RTC_Init(void)
{

  RTC_TimeTypeDef sTime = {0};
  RTC_DateTypeDef sDate = {0};

  /**Initialize RTC Only
  */
  hrtc.Instance = RTC;
  hrtc.Init.HourFormat = RTC_HOURFORMAT_24;
  hrtc.Init.AsynchPrediv = 127;
  hrtc.Init.SynchPrediv = 255;
  hrtc.Init.OutPut = RTC_OUTPUT_DISABLE;
  hrtc.Init.OutPutPolarity = RTC_OUTPUT_POLARITY_HIGH;
  hrtc.Init.OutPutType = RTC_OUTPUT_TYPE_OPENDRAIN;
  if (HAL_RTC_Init(&hrtc) != HAL_OK)
  {
    Error_Handler();
  }

  /**Initialize RTC and set the Time and Date
  */
  sTime.Hours = 0x0;
  sTime.Minutes = 0x0;
  sTime.Seconds = 0x0;
  sTime.DayLightSaving = RTC_DAYLIGHTSAVING_NONE;
  sTime.StoreOperation = RTC_STOREOPERATION_RESET;
  if (HAL_RTC_SetTime(&hrtc, &sTime, RTC_FORMAT_BCD) != HAL_OK)
  {
    Error_Handler();
  }
  sDate.WeekDay = RTC_WEEKDAY_MONDAY;
  sDate.Month = RTC_MONTH_JANUARY;
  sDate.Date = 0x1;
  sDate.Year = 0x0;

  if (HAL_RTC_SetDate(&hrtc, &sDate, RTC_FORMAT_BCD) != HAL_OK)
  {
    Error_Handler();
  }

}

static void MX_SPI1_Init(void)
{

  /* SPI1 parameter configuration*/
  hspi1.Instance = SPI1;
  hspi1.Init.Mode = SPI_MODE_MASTER;
  hspi1.Init.Direction = SPI_DIRECTION_1LINE;
  hspi1.Init.DataSize = SPI_DATASIZE_16BIT;
  hspi1.Init.CLKPolarity = SPI_POLARITY_LOW;
  hspi1.Init.CLKPhase = SPI_PHASE_1EDGE;
  hspi1.Init.NSS = SPI_NSS_HARD_OUTPUT;
  hspi1.Init.BaudRatePrescaler = SPI_BAUDRATEPRESCALER_64;
  hspi1.Init.FirstBit = SPI_FIRSTBIT_MSB;
  hspi1.Init.TIMode = SPI_TIMODE_DISABLE;
  hspi1.Init.CRCCalculation = SPI_CRCCALCULATION_DISABLE;
  hspi1.Init.CRCPolynomial = 10;
  if (HAL_SPI_Init(&hspi1) != HAL_OK)
  {
    Error_Handler();
  }

}

static void MX_TIM1_Init(void)
{

  TIM_ClockConfigTypeDef sClockSourceConfig = {0};
  TIM_MasterConfigTypeDef sMasterConfig = {0};
  TIM_OC_InitTypeDef sConfigOC = {0};
  TIM_BreakDeadTimeConfigTypeDef sBreakDeadTimeConfig = {0};

  htim1.Instance = TIM1;
  htim1.Init.Prescaler = 0;
  htim1.Init.CounterMode = TIM_COUNTERMODE_UP;
  htim1.Init.Period = 1050;
  htim1.Init.ClockDivision = TIM_CLOCKDIVISION_DIV1;
  htim1.Init.RepetitionCounter = 0;
  if (HAL_TIM_Base_Init(&htim1) != HAL_OK)
  {
    Error_Handler();
  }
  sClockSourceConfig.ClockSource = TIM_CLOCKSOURCE_INTERNAL;
  if (HAL_TIM_ConfigClockSource(&htim1, &sClockSourceConfig) != HAL_OK)
  {
    Error_Handler();
  }
  if (HAL_TIM_OC_Init(&htim1) != HAL_OK)
  {
    Error_Handler();
  }
  sMasterConfig.MasterOutputTrigger = TIM_TRGO_UPDATE;
  sMasterConfig.MasterSlaveMode = TIM_MASTERSLAVEMODE_DISABLE;
  if (HAL_TIMEx_MasterConfigSynchronization(&htim1, &sMasterConfig) != HAL_OK)
  {
    Error_Handler();
  }
  sConfigOC.OCMode = TIM_OCMODE_TIMING;
  sConfigOC.Pulse = 0;
  sConfigOC.OCPolarity = TIM_OCPOLARITY_HIGH;
  sConfigOC.OCNPolarity = TIM_OCNPOLARITY_HIGH;
  sConfigOC.OCFastMode = TIM_OCFAST_DISABLE;
  sConfigOC.OCIdleState = TIM_OCIDLESTATE_RESET;
  sConfigOC.OCNIdleState = TIM_OCNIDLESTATE_RESET;
  if (HAL_TIM_OC_ConfigChannel(&htim1, &sConfigOC, TIM_CHANNEL_1) != HAL_OK)
  {
    Error_Handler();
  }
  sBreakDeadTimeConfig.OffStateRunMode = TIM_OSSR_DISABLE;
  sBreakDeadTimeConfig.OffStateIDLEMode = TIM_OSSI_DISABLE;
  sBreakDeadTimeConfig.LockLevel = TIM_LOCKLEVEL_OFF;
  sBreakDeadTimeConfig.DeadTime = 0;
  sBreakDeadTimeConfig.BreakState = TIM_BREAK_DISABLE;
  sBreakDeadTimeConfig.BreakPolarity = TIM_BREAKPOLARITY_HIGH;
  sBreakDeadTimeConfig.AutomaticOutput = TIM_AUTOMATICOUTPUT_DISABLE;
  if (HAL_TIMEx_ConfigBreakDeadTime(&htim1, &sBreakDeadTimeConfig) != HAL_OK)
  {
    Error_Handler();
  }
  HAL_TIM_MspPostInit(&htim1);

}

static void MX_TIM2_Init(void)
{

  TIM_ClockConfigTypeDef sClockSourceConfig = {0};
  TIM_MasterConfigTypeDef sMasterConfig = {0};

  htim2.Instance = TIM2;
  htim2.Init.Prescaler = 21;
  htim2.Init.CounterMode = TIM_COUNTERMODE_UP;
  htim2.Init.Period = 500;
  htim2.Init.ClockDivision = TIM_CLOCKDIVISION_DIV1;
  if (HAL_TIM_Base_Init(&htim2) != HAL_OK)
  {
    Error_Handler();
  }
  sClockSourceConfig.ClockSource = TIM_CLOCKSOURCE_INTERNAL;
  if (HAL_TIM_ConfigClockSource(&htim2, &sClockSourceConfig) != HAL_OK)
  {
    Error_Handler();
  }
  sMasterConfig.MasterOutputTrigger = TIM_TRGO_UPDATE;
  sMasterConfig.MasterSlaveMode = TIM_MASTERSLAVEMODE_DISABLE;
  if (HAL_TIMEx_MasterConfigSynchronization(&htim2, &sMasterConfig) != HAL_OK)
  {
    Error_Handler();
  }

}

static void MX_TIM3_Init(void)
{

  TIM_ClockConfigTypeDef sClockSourceConfig = {0};
  TIM_MasterConfigTypeDef sMasterConfig = {0};
  TIM_OC_InitTypeDef sConfigOC = {0};

  htim3.Instance = TIM3;
  htim3.Init.Prescaler = 0;
  htim3.Init.CounterMode = TIM_COUNTERMODE_UP;
  htim3.Init.Period = 65535;
  htim3.Init.ClockDivision = TIM_CLOCKDIVISION_DIV1;
  if (HAL_TIM_Base_Init(&htim3) != HAL_OK)
  {
    Error_Handler();
  }
  sClockSourceConfig.ClockSource = TIM_CLOCKSOURCE_INTERNAL;
  if (HAL_TIM_ConfigClockSource(&htim3, &sClockSourceConfig) != HAL_OK)
  {
    Error_Handler();
  }
  if (HAL_TIM_PWM_Init(&htim3) != HAL_OK)
  {
    Error_Handler();
  }
  sMasterConfig.MasterOutputTrigger = TIM_TRGO_UPDATE;
  sMasterConfig.MasterSlaveMode = TIM_MASTERSLAVEMODE_DISABLE;
  if (HAL_TIMEx_MasterConfigSynchronization(&htim3, &sMasterConfig) != HAL_OK)
  {
    Error_Handler();
  }
  sConfigOC.OCMode = TIM_OCMODE_PWM1;
  sConfigOC.Pulse = 0;
  sConfigOC.OCPolarity = TIM_OCPOLARITY_HIGH;
  sConfigOC.OCFastMode = TIM_OCFAST_ENABLE;
  if (HAL_TIM_PWM_ConfigChannel(&htim3, &sConfigOC, TIM_CHANNEL_1) != HAL_OK)
  {
    Error_Handler();
  }
  HAL_TIM_MspPostInit(&htim3);

}

static void MX_TIM8_Init(void)
{

  TIM_ClockConfigTypeDef sClockSourceConfig = {0};
  TIM_MasterConfigTypeDef sMasterConfig = {0};

  htim8.Instance = TIM8;
  htim8.Init.Prescaler = 42000;
  htim8.Init.CounterMode = TIM_COUNTERMODE_UP;
  htim8.Init.Period = 25;
  htim8.Init.ClockDivision = TIM_CLOCKDIVISION_DIV4;
  htim8.Init.RepetitionCounter = 0;
  if (HAL_TIM_Base_Init(&htim8) != HAL_OK)
  {
    Error_Handler();
  }
  sClockSourceConfig.ClockSource = TIM_CLOCKSOURCE_INTERNAL;
  if (HAL_TIM_ConfigClockSource(&htim8, &sClockSourceConfig) != HAL_OK)
  {
    Error_Handler();
  }
  sMasterConfig.MasterOutputTrigger = TIM_TRGO_RESET;
  sMasterConfig.MasterSlaveMode = TIM_MASTERSLAVEMODE_DISABLE;
  if (HAL_TIMEx_MasterConfigSynchronization(&htim8, &sMasterConfig) != HAL_OK)
  {
    Error_Handler();
  }

}

static void MX_USART1_UART_Init(void)
{

  huart1.Instance = USART1;
  huart1.Init.BaudRate = 115200;
  huart1.Init.WordLength = UART_WORDLENGTH_8B;
  huart1.Init.StopBits = UART_STOPBITS_1;
  huart1.Init.Parity = UART_PARITY_NONE;
  huart1.Init.Mode = UART_MODE_TX_RX;
  huart1.Init.HwFlowCtl = UART_HWCONTROL_NONE;
  huart1.Init.OverSampling = UART_OVERSAMPLING_16;
  if (HAL_UART_Init(&huart1) != HAL_OK)
  {
    Error_Handler();
  }

}

static void MX_USB_OTG_FS_PCD_Init(void)
{

  hpcd_USB_OTG_FS.Instance = USB_OTG_FS;
  hpcd_USB_OTG_FS.Init.dev_endpoints = 4;
  hpcd_USB_OTG_FS.Init.speed = PCD_SPEED_FULL;
  hpcd_USB_OTG_FS.Init.dma_enable = DISABLE;
  hpcd_USB_OTG_FS.Init.ep0_mps = DEP0CTL_MPS_64;
  hpcd_USB_OTG_FS.Init.phy_itface = PCD_PHY_EMBEDDED;
  hpcd_USB_OTG_FS.Init.Sof_enable = DISABLE;
  hpcd_USB_OTG_FS.Init.low_power_enable = DISABLE;
  hpcd_USB_OTG_FS.Init.lpm_enable = DISABLE;
  hpcd_USB_OTG_FS.Init.vbus_sensing_enable = DISABLE;
  hpcd_USB_OTG_FS.Init.use_dedicated_ep1 = DISABLE;
  if (HAL_PCD_Init(&hpcd_USB_OTG_FS) != HAL_OK)
  {
    Error_Handler();
  }

}

static void MX_WWDG_Init(void)
{

  hwwdg.Instance = WWDG;
  hwwdg.Init.Prescaler = WWDG_PRESCALER_1;
  hwwdg.Init.Window = 64;
  hwwdg.Init.Counter = 64;
  hwwdg.Init.EWIMode = WWDG_EWI_DISABLE;
  if (HAL_WWDG_Init(&hwwdg) != HAL_OK)
  {
    Error_Handler();
  }

}

static void MX_DMA_Init(void)
{
  /* DMA controller clock enable */
  __HAL_RCC_DMA1_CLK_ENABLE();
  __HAL_RCC_DMA2_CLK_ENABLE();

  /* DMA interrupt init */
  /* DMA1_Stream0_IRQn interrupt configuration */
  HAL_NVIC_SetPriority(DMA1_Stream0_IRQn, 5, 0);
  HAL_NVIC_EnableIRQ(DMA1_Stream0_IRQn);
  /* DMA1_Stream7_IRQn interrupt configuration */
  HAL_NVIC_SetPriority(DMA1_Stream7_IRQn, 5, 0);
  HAL_NVIC_EnableIRQ(DMA1_Stream7_IRQn);
  /* DMA2_Stream0_IRQn interrupt configuration */
  HAL_NVIC_SetPriority(DMA2_Stream0_IRQn, 5, 0);
  HAL_NVIC_EnableIRQ(DMA2_Stream0_IRQn);
  /* DMA2_Stream1_IRQn interrupt configuration */
  HAL_NVIC_SetPriority(DMA2_Stream1_IRQn, 5, 0);
  HAL_NVIC_EnableIRQ(DMA2_Stream1_IRQn);
  /* DMA2_Stream2_IRQn interrupt configuration */
  HAL_NVIC_SetPriority(DMA2_Stream2_IRQn, 5, 0);
  HAL_NVIC_EnableIRQ(DMA2_Stream2_IRQn);
  /* DMA2_Stream3_IRQn interrupt configuration */
  HAL_NVIC_SetPriority(DMA2_Stream3_IRQn, 5, 0);
  HAL_NVIC_EnableIRQ(DMA2_Stream3_IRQn);
  /* DMA2_Stream4_IRQn interrupt configuration */
  HAL_NVIC_SetPriority(DMA2_Stream4_IRQn, 5, 0);
  HAL_NVIC_EnableIRQ(DMA2_Stream4_IRQn);
  /* DMA2_Stream5_IRQn interrupt configuration */
  HAL_NVIC_SetPriority(DMA2_Stream5_IRQn, 5, 0);
  HAL_NVIC_EnableIRQ(DMA2_Stream5_IRQn);
  /* DMA2_Stream7_IRQn interrupt configuration */
  HAL_NVIC_SetPriority(DMA2_Stream7_IRQn, 5, 0);
  HAL_NVIC_EnableIRQ(DMA2_Stream7_IRQn);

}

static void MX_GPIO_Init(void)
{
  GPIO_InitTypeDef GPIO_InitStruct = {0};

  /* GPIO Ports Clock Enable */
  __HAL_RCC_GPIOH_CLK_ENABLE();
  __HAL_RCC_GPIOC_CLK_ENABLE();
  __HAL_RCC_GPIOA_CLK_ENABLE();
  __HAL_RCC_GPIOB_CLK_ENABLE();
  __HAL_RCC_GPIOE_CLK_ENABLE();
  __HAL_RCC_GPIOD_CLK_ENABLE();

  /*Configure GPIO pin Output Level */
  HAL_GPIO_WritePin(GPIOC, RELAY_1_Pin|RELAY_2_Pin, GPIO_PIN_RESET);

  /*Configure GPIO pin Output Level */
  HAL_GPIO_WritePin(GPIOB, SS_Pin|SS_2_Pin|SS_3_Pin|U1_DE_Pin, GPIO_PIN_RESET);

  /*Configure GPIO pin Output Level */
  HAL_GPIO_WritePin(GPIOD, HG_1_Pin|HG_2_Pin|A_Pin|B_Pin
                          |C_Pin|D_Pin|E_Pin|F_Pin
                          |G_Pin|DP_Pin, GPIO_PIN_RESET);

  /*Configure GPIO pin Output Level */
  HAL_GPIO_WritePin(WC_GPIO_Port, WC_Pin, GPIO_PIN_RESET);

  /*Configure GPIO pins : RELAY_1_Pin RELAY_2_Pin */
  GPIO_InitStruct.Pin = RELAY_1_Pin|RELAY_2_Pin;
  GPIO_InitStruct.Mode = GPIO_MODE_OUTPUT_PP;
  GPIO_InitStruct.Pull = GPIO_NOPULL;
  GPIO_InitStruct.Speed = GPIO_SPEED_FREQ_LOW;
  HAL_GPIO_Init(GPIOC, &GPIO_InitStruct);

  /*Configure GPIO pins : SS_Pin SS_2_Pin SS_3_Pin */
  GPIO_InitStruct.Pin = SS_Pin|SS_2_Pin|SS_3_Pin;
  GPIO_InitStruct.Mode = GPIO_MODE_OUTPUT_PP;
  GPIO_InitStruct.Pull = GPIO_NOPULL;
  GPIO_InitStruct.Speed = GPIO_SPEED_FREQ_VERY_HIGH;
  HAL_GPIO_Init(GPIOB, &GPIO_InitStruct);

  /*Configure GPIO pins : HG_1_Pin HG_2_Pin A_Pin B_Pin
                           C_Pin D_Pin E_Pin F_Pin
                           G_Pin DP_Pin */
  GPIO_InitStruct.Pin = HG_1_Pin|HG_2_Pin|A_Pin|B_Pin
                          |C_Pin|D_Pin|E_Pin|F_Pin
                          |G_Pin|DP_Pin;
  GPIO_InitStruct.Mode = GPIO_MODE_OUTPUT_PP;
  GPIO_InitStruct.Pull = GPIO_NOPULL;
  GPIO_InitStruct.Speed = GPIO_SPEED_FREQ_LOW;
  HAL_GPIO_Init(GPIOD, &GPIO_InitStruct);

  /*Configure GPIO pin : BUT2_Pin */
  GPIO_InitStruct.Pin = BUT2_Pin;
  GPIO_InitStruct.Mode = GPIO_MODE_IT_RISING_FALLING;
  GPIO_InitStruct.Pull = GPIO_NOPULL;
  HAL_GPIO_Init(BUT2_GPIO_Port, &GPIO_InitStruct);

  /*Configure GPIO pin : BUT1_Pin */
  GPIO_InitStruct.Pin = BUT1_Pin;
  GPIO_InitStruct.Mode = GPIO_MODE_IT_RISING_FALLING;
  GPIO_InitStruct.Pull = GPIO_NOPULL;
  HAL_GPIO_Init(BUT1_GPIO_Port, &GPIO_InitStruct);

  /*Configure GPIO pin : U1_DE_Pin */
  GPIO_InitStruct.Pin = U1_DE_Pin;
  GPIO_InitStruct.Mode = GPIO_MODE_OUTPUT_PP;
  GPIO_InitStruct.Pull = GPIO_NOPULL;
  GPIO_InitStruct.Speed = GPIO_SPEED_FREQ_LOW;
  HAL_GPIO_Init(U1_DE_GPIO_Port, &GPIO_InitStruct);

  /*Configure GPIO pin : WC_Pin */
  GPIO_InitStruct.Pin = WC_Pin;
  GPIO_InitStruct.Mode = GPIO_MODE_OUTPUT_PP;
  GPIO_InitStruct.Pull = GPIO_NOPULL;
  GPIO_InitStruct.Speed = GPIO_SPEED_FREQ_LOW;
  HAL_GPIO_Init(WC_GPIO_Port, &GPIO_InitStruct);

  /* EXTI interrupt init*/
  HAL_NVIC_SetPriority(EXTI15_10_IRQn, 5, 0);
  HAL_NVIC_EnableIRQ(EXTI15_10_IRQn);

}

void StartDefaultTask(void const * argument)
{

  for(;;)
  {
    osDelay(1);
  }
}

void StartTask_S1(void const * argument)
{
  for(;;)
  {
    osDelay(1);
  }
}

void StartTask_S2(void const * argument)
{
  for(;;)
  {
    osDelay(1);
  }
}

void StartTaskModbus(void const * argument)
{
  for(;;)
  {
    osDelay(1);
  }
}

/* myTimerCallbackBUT2 function */
void myTimerCallbackBUT2(void const * argument)
{
}

/* myTimerCalbakBUT1 function */
void myTimerCalbakBUT1(void const * argument)
{
}

void Error_Handler(void)
{
}

/************************ (C) COPYRIGHT STMicroelectronics *****END OF FILE****/

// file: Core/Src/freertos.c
/* USER CODE BEGIN Header */
/**
  ******************************************************************************
  * File Name          : freertos.c
  * Description        : Code for freertos applications
  ******************************************************************************
  * This notice applies to any and all portions of this file
  * that are not between comment pairs USER CODE BEGIN and
  * USER CODE END. Other portions of this file, whether
  * inserted by the user or by software development tools
  * are owned by their respective copyright owners.
  *
  * Copyright (c) 2020 STMicroelectronics International N.V.
  * All rights reserved.
  *
  * Redistribution and use in source and binary forms, with or without
  * modification, are permitted, provided that the following conditions are met:
  *
  * 1. Redistribution of source code must retain the above copyright notice,
  *    this list of conditions and the following disclaimer.
  * 2. Redistributions in binary form must reproduce the above copyright notice,
  *    this list of conditions and the following disclaimer in the documentation
  *    and/or other materials provided with the distribution.
  * 3. Neither the name of STMicroelectronics nor the names of other
  *    contributors to this software may be used to endorse or promote products
  *    derived from this software without specific written permission.
  * 4. This software, including modifications and/or derivative works of this
  *    software, must execute solely and exclusively on microcontroller or
  *    microprocessor devices manufactured by or for STMicroelectronics.
  * 5. Redistribution and use of this software other than as permitted under
  *    this license is void and will automatically terminate your rights under
  *    this license.
  *
  * THIS SOFTWARE IS PROVIDED BY STMICROELECTRONICS AND CONTRIBUTORS "AS IS"
  * AND ANY EXPRESS, IMPLIED OR STATUTORY WARRANTIES, INCLUDING, BUT NOT
  * LIMITED TO, THE IMPLIED WARRANTIES OF MERCHANTABILITY, FITNESS FOR A
  * PARTICULAR PURPOSE AND NON-INFRINGEMENT OF THIRD PARTY INTELLECTUAL PROPERTY
  * RIGHTS ARE DISCLAIMED TO THE FULLEST EXTENT PERMITTED BY LAW. IN NO EVENT
  * SHALL STMICROELECTRONICS OR CONTRIBUTORS BE LIABLE FOR ANY DIRECT, INDIRECT,
  * INCIDENTAL, SPECIAL, EXEMPLARY, OR CONSEQUENTIAL DAMAGES (INCLUDING, BUT NOT
  * LIMITED TO, PROCUREMENT OF SUBSTITUTE GOODS OR SERVICES; LOSS OF USE, DATA,
  * OR PROFITS; OR BUSINESS INTERRUPTION) HOWEVER CAUSED AND ON ANY THEORY OF
  * LIABILITY, WHETHER IN CONTRACT, STRICT LIABILITY, OR TORT (INCLUDING
  * NEGLIGENCE OR OTHERWISE) ARISING IN ANY WAY OUT OF THE USE OF THIS SOFTWARE,
  * EVEN IF ADVISED OF THE POSSIBILITY OF SUCH DAMAGE.
  *
  ******************************************************************************
  */
/* USER CODE END Header */

#include "FreeRTOS.h"
#include "task.h"
#include "main.h"

/* GetIdleTaskMemory prototype (linked to static allocation support) */
void vApplicationGetIdleTaskMemory( StaticTask_t **ppxIdleTaskTCBBuffer, StackType_t **ppxIdleTaskStackBuffer, uint32_t *pulIdleTaskStackSize );

/* GetTimerTaskMemory prototype (linked to static allocation support) */
void vApplicationGetTimerTaskMemory( StaticTask_t **ppxTimerTaskTCBBuffer, StackType_t **ppxTimerTaskStackBuffer, uint32_t *pulTimerTaskStackSize );

/* Hook prototypes */
void vApplicationStackOverflowHook(xTaskHandle xTask, signed char *pcTaskName);

/* USER CODE BEGIN 4 */
__weak void vApplicationStackOverflowHook(xTaskHandle xTask, signed char *pcTaskName)
{
   /* Run time stack overflow checking is performed if
   configCHECK_FOR_STACK_OVERFLOW is defined to 1 or 2. This hook function is
   called if a stack overflow is detected. */
}
/* USER CODE END 4 */

/* USER CODE BEGIN GET_IDLE_TASK_MEMORY */
static StaticTask_t xIdleTaskTCBBuffer;
static StackType_t xIdleStack[configMINIMAL_STACK_SIZE];

void vApplicationGetIdleTaskMemory( StaticTask_t **ppxIdleTaskTCBBuffer, StackType_t **ppxIdleTaskStackBuffer, uint32_t *pulIdleTaskStackSize )
{
  *ppxIdleTaskTCBBuffer = &xIdleTaskTCBBuffer;
  *ppxIdleTaskStackBuffer = &xIdleStack[0];
  *pulIdleTaskStackSize = configMINIMAL_STACK_SIZE;
  /* place for user code */
}
/* USER CODE END GET_IDLE_TASK_MEMORY */

/* USER CODE BEGIN GET_TIMER_TASK_MEMORY */
static StaticTask_t xTimerTaskTCBBuffer;
static StackType_t xTimerStack[configTIMER_TASK_STACK_DEPTH];

void vApplicationGetTimerTaskMemory( StaticTask_t **ppxTimerTaskTCBBuffer, StackType_t **ppxTimerTaskStackBuffer, uint32_t *pulTimerTaskStackSize )
{
  *ppxTimerTaskTCBBuffer = &xTimerTaskTCBBuffer;
  *ppxTimerTaskStackBuffer = &xTimerStack[0];
  *pulTimerTaskStackSize = configTIMER_TASK_STACK_DEPTH;
  /* place for user code */
}
/* USER CODE END GET_TIMER_TASK_MEMORY */

/************************ (C) COPYRIGHT STMicroelectronics *****END OF FILE****/
